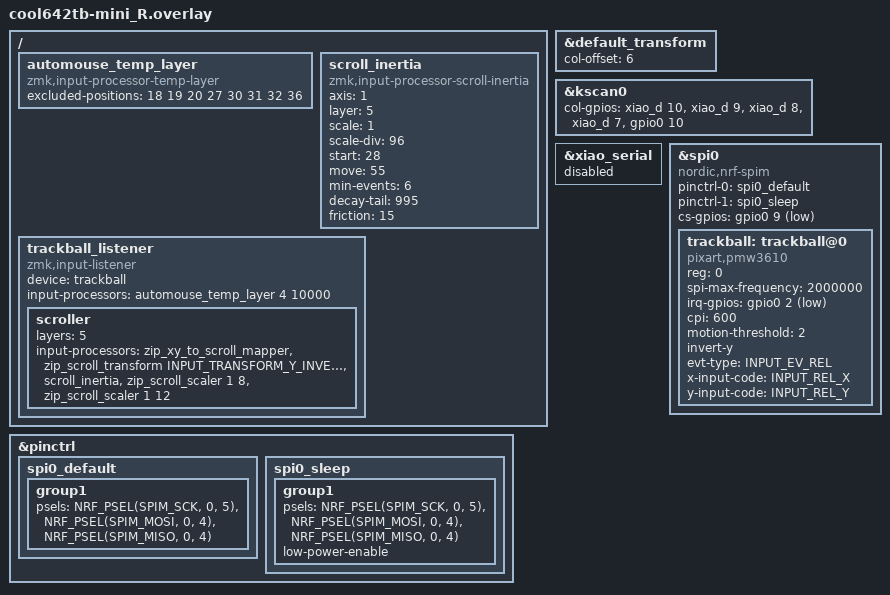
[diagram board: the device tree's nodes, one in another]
#include "cool642tb-mini.dtsi"
#include <zephyr/dt-bindings/input/input-event-codes.h>
#include <dt-bindings/zmk/input_transform.h>
#include <input/processors.dtsi>

&default_transform {
    col-offset = <6>;
};

&kscan0 {
        col-gpios
            = <&xiao_d 10 GPIO_ACTIVE_HIGH>
            , <&xiao_d 9 GPIO_ACTIVE_HIGH> 
            , <&xiao_d 8 GPIO_ACTIVE_HIGH> 
            , <&xiao_d 7 GPIO_ACTIVE_HIGH> 
            , <&gpio0 10 GPIO_ACTIVE_HIGH>
            ;
};

/ {
    automouse_temp_layer: automouse_temp_layer {
        compatible = "zmk,input-processor-temp-layer";
        #input-processor-cells = <2>;
        excluded-positions = <18 19 20 27 30 31 32 36>;
    };

    scroll_inertia: scroll_inertia {
        compatible = "zmk,input-processor-scroll-inertia";
        #input-processor-cells = <0>;

        axis = <1>;
        layer = <5>;

        scale = <1>;
        scale-div = <96>;

        start = <28>;
        move = <55>;
        min-events = <6>;

        decay-tail = <995>;
        friction = <15>;
    };

    trackball_listener {
        compatible = "zmk,input-listener";
        device = <&trackball>;

        input-processors = <&automouse_temp_layer 4 10000>;

        scroller {
            layers = <5>;
            input-processors =
                <&zip_xy_to_scroll_mapper>,
                <&zip_scroll_transform INPUT_TRANSFORM_Y_INVERT>,
                <&scroll_inertia>,
                <&zip_scroll_scaler 1 8>,
                <&zip_scroll_scaler 1 12>;
        };
    };
};

&pinctrl {
    spi0_default: spi0_default {
        group1 {
            psels = <NRF_PSEL(SPIM_SCK, 0, 5)>,
                <NRF_PSEL(SPIM_MOSI, 0, 4)>,
                <NRF_PSEL(SPIM_MISO, 0, 4)>;
        };
    };

    spi0_sleep: spi0_sleep {
        group1 {
            psels = <NRF_PSEL(SPIM_SCK, 0, 5)>,
                <NRF_PSEL(SPIM_MOSI, 0, 4)>,
                <NRF_PSEL(SPIM_MISO, 0, 4)>;
            low-power-enable;
        };
    };
};

&xiao_serial { status = "disabled"; };

&spi0 {
    status = "okay";
    compatible = "nordic,nrf-spim";
    pinctrl-0 = <&spi0_default>;
    pinctrl-1 = <&spi0_sleep>;
    pinctrl-names = "default", "sleep";
    cs-gpios = <&gpio0 9 GPIO_ACTIVE_LOW>;

trackball: trackball@0 {
    status = "okay";
    compatible = "pixart,pmw3610";
    reg = <0>;
    spi-max-frequency = <2000000>;
    irq-gpios = <&gpio0 2 (GPIO_ACTIVE_LOW | GPIO_PULL_UP)>;

    cpi = <600>;
    motion-threshold = <2>;

    invert-y;

    evt-type = <INPUT_EV_REL>;
    x-input-code = <INPUT_REL_X>;
    y-input-code = <INPUT_REL_Y>;

};
};
